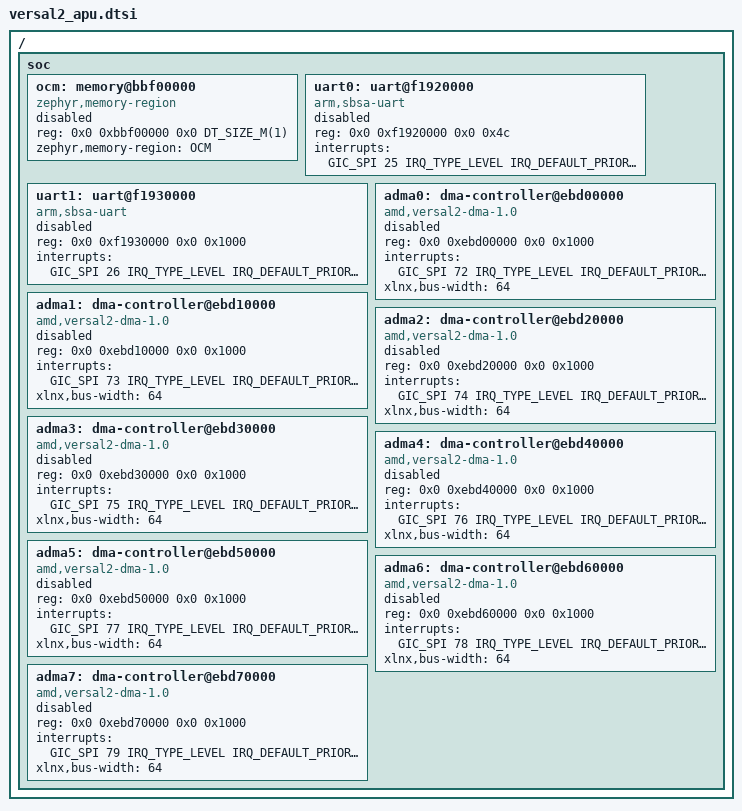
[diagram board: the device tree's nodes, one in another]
/*
 * Copyright (c) 2025, Advanced Micro Devices, Inc.
 *
 * SPDX-License-Identifier: Apache-2.0
 */

/ {
	soc: soc {
		#address-cells = <2>;
		#size-cells = <2>;
		ranges;

		/*
		 * OCM (On-Chip Memory) is used by TF-A (Trusted Firmware-A) by default.
		 * Enable this node only if TF-A is not using this memory region or if
		 * explicit coordination is established between TF-A and Zephyr.
		 */
		ocm: memory@bbf00000 {
			compatible = "zephyr,memory-region";
			reg = <0x0 0xbbf00000 0x0 DT_SIZE_M(1)>;
			status = "disabled";
			zephyr,memory-region = "OCM";
		};

		uart0: uart@f1920000 {
			compatible = "arm,sbsa-uart";
			reg = <0x0 0xf1920000 0x0 0x4c>;
			status = "disabled";
			interrupt-names = "irq_25";
			interrupts = <GIC_SPI 25 IRQ_TYPE_LEVEL IRQ_DEFAULT_PRIORITY>;
		};

		uart1: uart@f1930000 {
			compatible = "arm,sbsa-uart";
			reg = <0x0 0xf1930000 0x0 0x1000>;
			status = "disabled";
			interrupt-names = "irq_26";
			interrupts = <GIC_SPI 26 IRQ_TYPE_LEVEL IRQ_DEFAULT_PRIORITY>;
		};

		adma0: dma-controller@ebd00000 {
			compatible = "amd,versal2-dma-1.0";
			status = "disabled";
			reg = <0x0 0xebd00000 0x0 0x1000>;
			#dma-cells = <1>;
			interrupts = <GIC_SPI 72 IRQ_TYPE_LEVEL IRQ_DEFAULT_PRIORITY>;
			clock-names = "clk_main", "clk_apb";
			xlnx,bus-width = <64>;
		};

		adma1: dma-controller@ebd10000 {
			compatible = "amd,versal2-dma-1.0";
			status = "disabled";
			reg = <0x0 0xebd10000 0x0 0x1000>;
			#dma-cells = <1>;
			interrupts = <GIC_SPI 73 IRQ_TYPE_LEVEL IRQ_DEFAULT_PRIORITY>;
			clock-names = "clk_main", "clk_apb";
			xlnx,bus-width = <64>;
		};

		adma2: dma-controller@ebd20000 {
			compatible = "amd,versal2-dma-1.0";
			status = "disabled";
			reg = <0x0 0xebd20000 0x0 0x1000>;
			#dma-cells = <1>;
			interrupts = <GIC_SPI 74 IRQ_TYPE_LEVEL IRQ_DEFAULT_PRIORITY>;
			clock-names = "clk_main", "clk_apb";
			xlnx,bus-width = <64>;
		};

		adma3: dma-controller@ebd30000 {
			compatible = "amd,versal2-dma-1.0";
			status = "disabled";
			reg = <0x0 0xebd30000 0x0 0x1000>;
			#dma-cells = <1>;
			interrupts = <GIC_SPI 75 IRQ_TYPE_LEVEL IRQ_DEFAULT_PRIORITY>;
			clock-names = "clk_main", "clk_apb";
			xlnx,bus-width = <64>;
		};

		adma4: dma-controller@ebd40000 {
			compatible = "amd,versal2-dma-1.0";
			status = "disabled";
			reg = <0x0 0xebd40000 0x0 0x1000>;
			#dma-cells = <1>;
			interrupts = <GIC_SPI 76 IRQ_TYPE_LEVEL IRQ_DEFAULT_PRIORITY>;
			clock-names = "clk_main", "clk_apb";
			xlnx,bus-width = <64>;
		};

		adma5: dma-controller@ebd50000 {
			compatible = "amd,versal2-dma-1.0";
			status = "disabled";
			reg = <0x0 0xebd50000 0x0 0x1000>;
			#dma-cells = <1>;
			interrupts = <GIC_SPI 77 IRQ_TYPE_LEVEL IRQ_DEFAULT_PRIORITY>;
			clock-names = "clk_main", "clk_apb";
			xlnx,bus-width = <64>;
		};

		adma6: dma-controller@ebd60000 {
			compatible = "amd,versal2-dma-1.0";
			status = "disabled";
			reg = <0x0 0xebd60000 0x0 0x1000>;
			#dma-cells = <1>;
			interrupts = <GIC_SPI 78 IRQ_TYPE_LEVEL IRQ_DEFAULT_PRIORITY>;
			clock-names = "clk_main", "clk_apb";
			xlnx,bus-width = <64>;
		};

		adma7: dma-controller@ebd70000 {
			compatible = "amd,versal2-dma-1.0";
			status = "disabled";
			reg = <0x0 0xebd70000 0x0 0x1000>;
			#dma-cells = <1>;
			interrupts = <GIC_SPI 79 IRQ_TYPE_LEVEL IRQ_DEFAULT_PRIORITY>;
			clock-names = "clk_main", "clk_apb";
			xlnx,bus-width = <64>;
		};
	};
};
